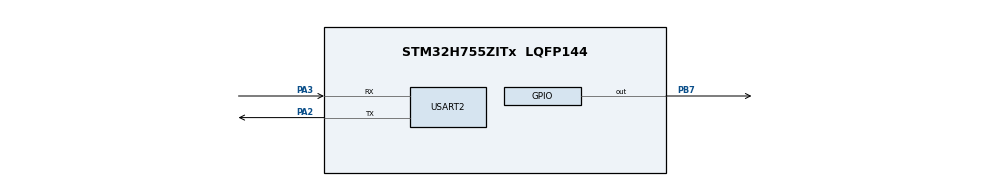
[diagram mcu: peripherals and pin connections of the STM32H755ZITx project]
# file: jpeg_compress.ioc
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CORTEX_M4.Enable-Cortex_Memory_Protection_Unit_Region0_Settings=__NULL
CORTEX_M4.MPU_Control=MPU_PRIVILEGED_DEFAULT
CORTEX_M7.default_mode_Activation=1
CortexM4.IPs=BDMA,CORTEX_M4\:I,DMA,FATFS_M4\:I,FREERTOS_M4\:I,GPIO,IWDG2\:I,MDMA,NVIC2\:I,OPENAMP_M4\:I,PDM2PCM_M4\:I,PWR,RCC,RESMGR_UTILITY,SYS_M4\:I,USB_DEVICE_M4\:I,USB_HOST_M4\:I,VREFBUF,WWDG2\:I
CortexM7.IPs=BDMA\:I,CORTEX_M7\:I,DMA\:I,FATFS_M7\:I,FREERTOS_M7\:I,GPIO\:I,IWDG1\:I,MDMA\:I,NVIC1\:I,OPENAMP_M7\:I,PDM2PCM_M7\:I,PWR\:I,RCC\:I,RESMGR_UTILITY\:I,SYS\:I,USB_DEVICE_M7\:I,USB_HOST_M7\:I,VREFBUF\:I,WWDG1\:I,MEMORYMAP\:I,JPEG\:I,USART2\:I,RNG\:I
Mcu.Family=STM32H7
Mcu.Name=STM32H755ZITx
Mcu.Package=LQFP144
NVIC1.PriorityGroup=NVIC_PRIORITYGROUP_4
NVIC1.USART2_IRQn=true\:0\:0\:false\:false\:true\:true\:true\:true
NVIC2.PriorityGroup=NVIC_PRIORITYGROUP_4
PA2.Mode=Asynchronous
PA2.PinAttribute=CortexM7
PA2.Signal=USART2_TX
PA3.Mode=Asynchronous
PA3.PinAttribute=CortexM7
PA3.Signal=USART2_RX
PB7.PinAttribute=Free
PB7.Signal=GPIO_Output
ProjectManager.HeapSize=M4-0x200,M7-0x200
ProjectManager.StackSize=M4-0x400,M7-0x400
ProjectManager.TargetToolchain=STM32CubeIDE
RCC.ADCFreq_Value=129000000
RCC.APB1Freq_Value=32000000
RCC.APB2Freq_Value=64000000
RCC.APB3Freq_Value=64000000
RCC.APB4Freq_Value=64000000
RCC.CortexFreq_Value=64000000
RCC.D2PPRE1=RCC_APB1_DIV2
RCC.HCLKFreq_Value=64000000
RCC.SYSCLKFreq_VALUE=64000000
RCC.USBFreq_Value=129000000
SYS.userName=SYS_M7
USART2.VirtualMode-Asynchronous=VM_ASYNC
VP_JPEG_VS_JPEG.Mode=JPEG_Activate
VP_MEMORYMAP_VS_MEMORYMAP.Mode=CurAppReg
VP_RNG_VS_RNG.Mode=RNG_Activate
VP_SYS_M4_VS_Systick.Mode=SysTick
board=custom

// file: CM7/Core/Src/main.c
/* USER CODE BEGIN Header */
/**
 ******************************************************************************
 * @file           : main.c
 * @brief          : Main program body
 ******************************************************************************
 * @attention
 *
 * Copyright (c) 2025 STMicroelectronics.
 * All rights reserved.
 *
 * This software is licensed under terms that can be found in the LICENSE file
 * in the root directory of this software component.
 * If no LICENSE file comes with this software, it is provided AS-IS.
 *
 ******************************************************************************
 */
/* USER CODE END Header */
#include "main.h"

/* USER CODE BEGIN Includes */
#include <stdio.h>
#include <stdlib.h>
#include <string.h>
#include <stdarg.h>
/* USER CODE END Includes */

/* USER CODE BEGIN PD */
#ifndef HSEM_ID_0
#define HSEM_ID_0 (0U) /* HW semaphore 0*/
#endif
/* USER CODE END PD */

/* USER CODE BEGIN PM */
#define CHUNK_SIZE 4096
#define RAW_IMAGE_SIZE 16384 // 128x128 square image
#define UART_BUF 128
/* USER CODE END PM */

JPEG_HandleTypeDef hjpeg;

RNG_HandleTypeDef hrng;

UART_HandleTypeDef huart2;

/* USER CODE BEGIN PV */
char TX_buf[16];
uint8_t raw_image[RAW_IMAGE_SIZE];  // Raw pixel data (RGB)
uint8_t jpeg_output[JPEG_OUTPUT_SIZE];  // JPEG compressed output
/* USER CODE END PV */

void SystemClock_Config(void);
static void MPU_Config(void);
static void MX_GPIO_Init(void);
static void MX_JPEG_Init(void);
static void MX_USART2_UART_Init(void);
static void MX_RNG_Init(void);

/* USER CODE BEGIN 0 */
// Cooler UART printf that was definitely not just generated with chatgpt along with 90% of this program
int UART_printf(const char *fmt, ...) {
	char buf[UART_BUF];
	va_list args;
	int len;

	va_start(args, fmt);
	len = vsnprintf(buf, sizeof(buf), fmt, args);
	va_end(args);

	HAL_UART_Transmit(&huart2, (uint8_t*) buf, len, HAL_MAX_DELAY);

	return len;
}

// Reads a chunk of the JPEG, returns number bytes read
size_t read_jpeg_chunk(uint8_t *buffer, size_t max_size, size_t offset) {
	size_t jpegSize;

	if (offset >= jpegSize) {
		return 0; // No more data
	}

	size_t bytes_to_read;
	if ((jpegSize - offset) < max_size) {
		bytes_to_read = jpegSize - offset;
	} else {
		bytes_to_read = max_size;
	}
	// Copy chunk into buffer
	memcpy(buffer, &jpeg_output[offset], bytes_to_read);
	return bytes_to_read;
}

// Transmits JPEG in bytes
void transmit_jpeg() {
	uint8_t buf[CHUNK_SIZE];
	size_t offset = 0; // Keeps track of the current read position
	size_t bytesRead;

	// Keep transmitting until there are no more bytes left
	while ((bytesRead = read_jpeg_chunk(buf, CHUNK_SIZE, offset)) > 0) {
		// Transmit current chunk and handle error
		if (HAL_UART_Transmit(&huart2, buf, bytesRead, HAL_MAX_DELAY)
				!= HAL_OK) {
			break;
		}
		offset += bytesRead;
	}
}

// Generates a number from 0-255 (need a function for this, HAL_RNG gives a 32-bit num)
uint8_t random_8bit_num(void) {
	uint32_t random;
	if (HAL_RNG_GenerateRandomNumber(&hrng, &random) == HAL_OK) {
		// Map random number to 0-255
		return (uint8_t) (random % 256);
	} else
		return 0; // just in case :)
}

// Compresses a raw 24-bit RGB random image into JPEG format
void compress_random_image() {
	HAL_StatusTypeDef status;

	// Generating image with a bunch of random colours
	for (uint32_t i = 0; i < RAW_IMAGE_SIZE; i += 3) {
		raw_image[i] = random_8bit_num();   	// R
		raw_image[i + 1] = random_8bit_num();   // G
		raw_image[i + 2] = random_8bit_num(); 	// B
	}

	status = HAL_JPEG_Encode(&hjpeg, raw_image, RAW_IMAGE_SIZE, jpeg_output,
			JPEG_BUFFER_SIZE,
			HAL_MAX_DELAY);

	if (status == HAL_OK) {
		printf("JPEG Encoding Done\n");
		// Here, you can, for example, send jpeg_output over UART, store it to SD card, etc.
	} else {
		// Handle the error
		printf("JPEG Encoding Failed!\n");
	}
}

void log()
/* USER CODE END 0 */

int main(void) {

	/* USER CODE BEGIN Boot_Mode_Sequence_0 */
	int32_t timeout;
	/* USER CODE END Boot_Mode_Sequence_0 */

	/* MPU Configuration--------------------------------------------------------*/
	MPU_Config();

	/* USER CODE BEGIN Boot_Mode_Sequence_1 */
	/* Wait until CPU2 boots and enters in stop mode or timeout*/
	timeout = 0xFFFF;
	while ((__HAL_RCC_GET_FLAG(RCC_FLAG_D2CKRDY) != RESET) && (timeout-- > 0))
		;
	if (timeout < 0) {
		Error_Handler();
	}
	/* USER CODE END Boot_Mode_Sequence_1 */
	/* MCU Configuration--------------------------------------------------------*/

	/* Reset of all peripherals, Initializes the Flash interface and the Systick. */
	HAL_Init();

	/* Configure the system clock */
	SystemClock_Config();
	/* USER CODE BEGIN Boot_Mode_Sequence_2 */
	/* When system initialization is finished, Cortex-M7 will release Cortex-M4 by means of
	 HSEM notification */
	/*HW semaphore Clock enable*/
	__HAL_RCC_HSEM_CLK_ENABLE();
	/*Take HSEM */
	HAL_HSEM_FastTake(HSEM_ID_0);
	/*Release HSEM in order to notify the CPU2(CM4)*/
	HAL_HSEM_Release(HSEM_ID_0, 0);
	/* wait until CPU2 wakes up from stop mode */
	timeout = 0xFFFF;
	while ((__HAL_RCC_GET_FLAG(RCC_FLAG_D2CKRDY) == RESET) && (timeout-- > 0))
		;
	if (timeout < 0) {
		Error_Handler();
	}
	/* USER CODE END Boot_Mode_Sequence_2 */

	/* Initialize all configured peripherals */
	MX_GPIO_Init();
	MX_JPEG_Init();
	MX_USART2_UART_Init();
	MX_RNG_Init();
	/* USER CODE BEGIN 2 */
	// read_matrix("image_data.txt", image);
	// print_matrix(image);
	HAL_JPEG_Encode(&hjpeg, pDataInMCU, InDataLength, pDataOut, OutDataLength,
			Timeout);
	//HAL_UART_Transmit(&huart2, (uint8_t*) "Done!", 32, 10);
	UART_printf("Done!");
	/* USER CODE END 2 */

	/* Infinite loop */
	while (1) {

	}
}

void SystemClock_Config(void) {
	RCC_OscInitTypeDef RCC_OscInitStruct = { 0 };
	RCC_ClkInitTypeDef RCC_ClkInitStruct = { 0 };

	/** Supply configuration update enable
	 */
	HAL_PWREx_ConfigSupply(PWR_DIRECT_SMPS_SUPPLY);

	/** Configure the main internal regulator output voltage
	 */
	__HAL_PWR_VOLTAGESCALING_CONFIG(PWR_REGULATOR_VOLTAGE_SCALE3);

	while (!__HAL_PWR_GET_FLAG(PWR_FLAG_VOSRDY)) {
	}

	/** Initializes the RCC Oscillators according to the specified parameters
	 * in the RCC_OscInitTypeDef structure.
	 */
	RCC_OscInitStruct.OscillatorType = RCC_OSCILLATORTYPE_HSI48
			| RCC_OSCILLATORTYPE_HSI;
	RCC_OscInitStruct.HSIState = RCC_HSI_DIV1;
	RCC_OscInitStruct.HSICalibrationValue = RCC_HSICALIBRATION_DEFAULT;
	RCC_OscInitStruct.HSI48State = RCC_HSI48_ON;
	RCC_OscInitStruct.PLL.PLLState = RCC_PLL_NONE;
	if (HAL_RCC_OscConfig(&RCC_OscInitStruct) != HAL_OK) {
		Error_Handler();
	}

	/** Initializes the CPU, AHB and APB buses clocks
	 */
	RCC_ClkInitStruct.ClockType = RCC_CLOCKTYPE_HCLK | RCC_CLOCKTYPE_SYSCLK
			| RCC_CLOCKTYPE_PCLK1 | RCC_CLOCKTYPE_PCLK2 | RCC_CLOCKTYPE_D3PCLK1
			| RCC_CLOCKTYPE_D1PCLK1;
	RCC_ClkInitStruct.SYSCLKSource = RCC_SYSCLKSOURCE_HSI;
	RCC_ClkInitStruct.SYSCLKDivider = RCC_SYSCLK_DIV1;
	RCC_ClkInitStruct.AHBCLKDivider = RCC_HCLK_DIV1;
	RCC_ClkInitStruct.APB3CLKDivider = RCC_APB3_DIV1;
	RCC_ClkInitStruct.APB1CLKDivider = RCC_APB1_DIV2;
	RCC_ClkInitStruct.APB2CLKDivider = RCC_APB2_DIV1;
	RCC_ClkInitStruct.APB4CLKDivider = RCC_APB4_DIV1;

	if (HAL_RCC_ClockConfig(&RCC_ClkInitStruct, FLASH_LATENCY_1) != HAL_OK) {
		Error_Handler();
	}
}

static void MX_JPEG_Init(void) {

	hjpeg.Instance = JPEG;
	if (HAL_JPEG_Init(&hjpeg) != HAL_OK) {
		Error_Handler();
	}

}

static void MX_RNG_Init(void) {

	hrng.Instance = RNG;
	hrng.Init.ClockErrorDetection = RNG_CED_ENABLE;
	if (HAL_RNG_Init(&hrng) != HAL_OK) {
		Error_Handler();
	}

}

static void MX_USART2_UART_Init(void) {

	huart2.Instance = USART2;
	huart2.Init.BaudRate = 115200;
	huart2.Init.WordLength = UART_WORDLENGTH_8B;
	huart2.Init.StopBits = UART_STOPBITS_1;
	huart2.Init.Parity = UART_PARITY_NONE;
	huart2.Init.Mode = UART_MODE_TX_RX;
	huart2.Init.HwFlowCtl = UART_HWCONTROL_NONE;
	huart2.Init.OverSampling = UART_OVERSAMPLING_16;
	huart2.Init.OneBitSampling = UART_ONE_BIT_SAMPLE_DISABLE;
	huart2.Init.ClockPrescaler = UART_PRESCALER_DIV1;
	huart2.AdvancedInit.AdvFeatureInit = UART_ADVFEATURE_NO_INIT;
	if (HAL_UART_Init(&huart2) != HAL_OK) {
		Error_Handler();
	}
	if (HAL_UARTEx_SetTxFifoThreshold(&huart2, UART_TXFIFO_THRESHOLD_1_8)
			!= HAL_OK) {
		Error_Handler();
	}
	if (HAL_UARTEx_SetRxFifoThreshold(&huart2, UART_RXFIFO_THRESHOLD_1_8)
			!= HAL_OK) {
		Error_Handler();
	}
	if (HAL_UARTEx_DisableFifoMode(&huart2) != HAL_OK) {
		Error_Handler();
	}

}

static void MX_GPIO_Init(void) {

	/* GPIO Ports Clock Enable */
	__HAL_RCC_GPIOA_CLK_ENABLE();

}

/* MPU Configuration */

void MPU_Config(void) {
	MPU_Region_InitTypeDef MPU_InitStruct = { 0 };

	/* Disables the MPU */
	HAL_MPU_Disable();

	/** Initializes and configures the Region and the memory to be protected
	 */
	MPU_InitStruct.Enable = MPU_REGION_ENABLE;
	MPU_InitStruct.Number = MPU_REGION_NUMBER0;
	MPU_InitStruct.BaseAddress = 0x0;
	MPU_InitStruct.Size = MPU_REGION_SIZE_4GB;
	MPU_InitStruct.SubRegionDisable = 0x87;
	MPU_InitStruct.TypeExtField = MPU_TEX_LEVEL0;
	MPU_InitStruct.AccessPermission = MPU_REGION_NO_ACCESS;
	MPU_InitStruct.DisableExec = MPU_INSTRUCTION_ACCESS_DISABLE;
	MPU_InitStruct.IsShareable = MPU_ACCESS_SHAREABLE;
	MPU_InitStruct.IsCacheable = MPU_ACCESS_NOT_CACHEABLE;
	MPU_InitStruct.IsBufferable = MPU_ACCESS_NOT_BUFFERABLE;

	HAL_MPU_ConfigRegion(&MPU_InitStruct);
	/* Enables the MPU */
	HAL_MPU_Enable(MPU_PRIVILEGED_DEFAULT);

}

void Error_Handler(void) {
	__disable_irq();
	while (1) {
	}
}
